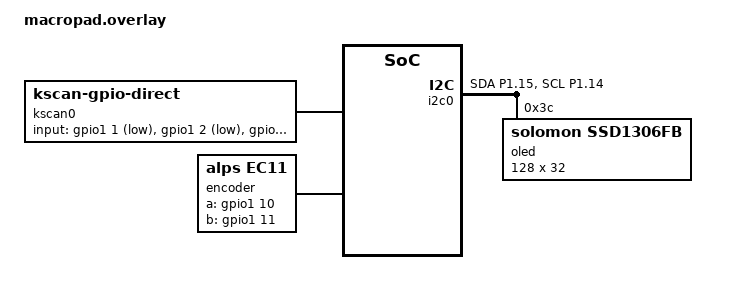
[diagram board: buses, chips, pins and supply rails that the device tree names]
#include <dt-bindings/gpio/gpio.h>

&pinctrl {
    i2c0_default_custom: i2c0_default_custom {
        group1 {
            psels = <NRF_PSEL(TWIM_SDA, 1, 15)>,
                    <NRF_PSEL(TWIM_SCL, 1, 14)>;
            bias-pull-up;
        };
    };

    i2c0_sleep_custom: i2c0_sleep_custom {
        group1 {
            psels = <NRF_PSEL(TWIM_SDA, 1, 15)>,
                    <NRF_PSEL(TWIM_SCL, 1, 14)>;
            low-power-enable;
        };
    };
};

/ {
    chosen {
        zmk,kscan = &kscan0;
        zephyr,display = &oled;
    };

    kscan0: kscan_0 {
        compatible = "zmk,kscan-gpio-direct";
        input-gpios
            = <&gpio1 1 (GPIO_ACTIVE_LOW | GPIO_PULL_UP)>
            , <&gpio1 2 (GPIO_ACTIVE_LOW | GPIO_PULL_UP)>
            , <&gpio1 3 (GPIO_ACTIVE_LOW | GPIO_PULL_UP)>
            , <&gpio1 4 (GPIO_ACTIVE_LOW | GPIO_PULL_UP)>
            , <&gpio1 5 (GPIO_ACTIVE_LOW | GPIO_PULL_UP)>
            , <&gpio1 6 (GPIO_ACTIVE_LOW | GPIO_PULL_UP)>
            , <&gpio1 7 (GPIO_ACTIVE_LOW | GPIO_PULL_UP)>
            , <&gpio1 8 (GPIO_ACTIVE_LOW | GPIO_PULL_UP)>
            , <&gpio1 9 (GPIO_ACTIVE_LOW | GPIO_PULL_UP)>
            ;
    };

    encoder: encoder {
        compatible = "alps,ec11";
        a-gpios = <&gpio1 10 (GPIO_ACTIVE_HIGH | GPIO_PULL_UP)>;
        b-gpios = <&gpio1 11 (GPIO_ACTIVE_HIGH | GPIO_PULL_UP)>;
        steps = <80>;
        status = "okay";
    };

    sensors {
        compatible = "zmk,keymap-sensors";
        sensors = <&encoder>;
    };
};

&i2c0 {
    status = "okay";
    // Hier verknüpfen wir jetzt deine oben definierten Custom-Pins (1.15 und 1.14)
    pinctrl-0 = <&i2c0_default_custom>;
    pinctrl-1 = <&i2c0_sleep_custom>;
    pinctrl-names = "default", "sleep";

    oled: ssd1306@3c {
        compatible = "solomon,ssd1306fb";
        reg = <0x3c>;
        width = <128>;
        height = <32>;
        segment-offset = <0>;
        page-offset = <0>;
        display-offset = <0>;
        multiplex-ratio = <31>;
        segment-remap;
        com-invdir;
        com-sequential;
        prechargep = <0x22>;
    };
};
